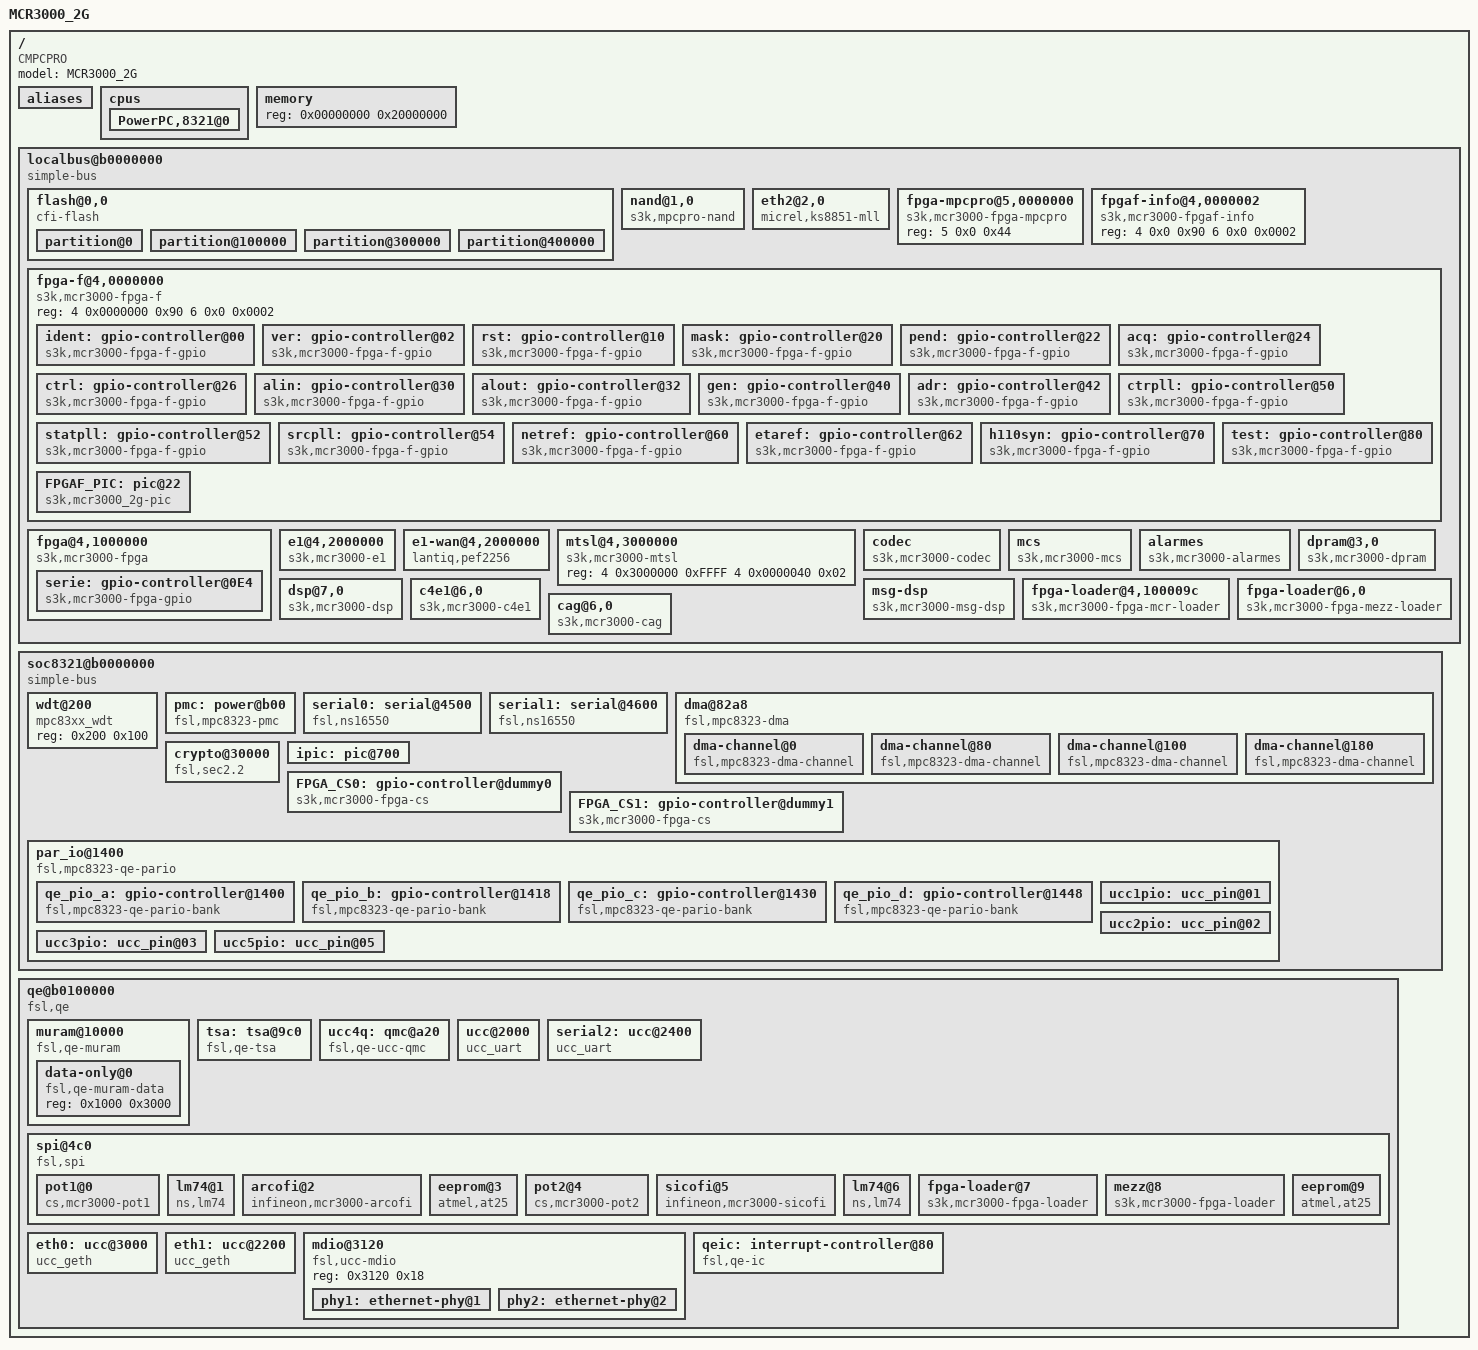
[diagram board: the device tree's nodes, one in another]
/*
 * MPC8321E Device Tree Source
 *
 * Copyright 2007 Freescale Semiconductor Inc.
 *
 * This program is free software; you can redistribute  it and/or modify it
 * under  the terms of  the GNU General  Public License as published by the
 * Free Software Foundation;  either version 2 of the  License, or (at your
 * option) any later version.
 */

/dts-v1/;

/ {
	model = "MCR3000_2G";
	compatible = "CMPCPRO", "MPC8321E", "MPC8323ERDB", "MPC832xRDB", "MPC83xxRDB", "fsl,base", "fsl,mpcpro";
	#address-cells = <1>;
	#size-cells = <1>;

	aliases {
		ethernet0 = &eth1;
		ethernet1 = &eth0;
		serial0 = &serial0;
		serial1 = &serial1;
		serial2 = &serial2;
	};

	cpus {
		#address-cells = <1>;
		#size-cells = <0>;

		PowerPC,8321@0 {
			device_type = "cpu";
			reg = <0x0>;
			d-cache-line-size = <0x20>;	// 32 bytes
			i-cache-line-size = <0x20>;	// 32 bytes
			d-cache-size = <16384>;	// L1, 16K
			i-cache-size = <16384>;	// L1, 16K
			timebase-frequency = <0>;
			bus-frequency = <0>;
			clock-frequency = <0>;
		};
	};

	memory {
		device_type = "memory";
		reg = <0x00000000 0x20000000>;
	};

	localbus@b0000000 {
		#address-cells = <2>;
		#size-cells = <1>;
		compatible = "simple-bus";
		ranges = <0 0x0 0x40000000 0x04000000	// Boot Flash
			  1 0x0 0xa0000000 0x00008000	// Nand Flash
			  2 0x0 0x92000000 0x00008000	// Eth Face avant
			  3 0x0 0x83400000 0x00010000	// DPRAM (DSP)
			  4 0x0 0x80000000 0x10000000	// Periphs
			  5 0x0 0x90000000 0x10000000	// FPGA-MPCPRO
			  6 0x0 0x81800000 0x00008000	// mezzanine
			  7 0x0 0x80800000 0x00008000>;	// DSP

//			  5 0x0 0x80000000 0x00800000>;	// FPGA-Firmware
//			  6 0x0 0x80800000 0x00800000	// DSP
//			  7 0x0 0x81000000 0x00800000	// FPGA-Radio
//			  8 0x0 0x81800000 0x00800000	// mezzanine
//			  9 0x0 0x82000000 0x00800000	// controleur E1
//			 10 0x0 0x83000000 0x00400000	// matrice
//			 11 0x0 0x83400000 0x00800000	// DPRAM (DSP)
//			 12 0x0 0x83c00000 0x00800000>;	// DPRAM (semaphores)
		reg = <0xb0000000 0x00000200>;
		bus-frequency = <0>;

		flash@0,0 {
			#address-cells = <1>;
			#size-cells = <1>;
			compatible = "cfi-flash";
			reg = <0x0 0x00000000 0x4000000>;
			bank-width = <2>;
			device-width = <2>;
			partition@0 {
				label = "boot";
				reg = <0x0 0x100000>;
			};
			partition@100000 {
				label = "other u-boot";
				reg = <0x100000 0x200000>;
			};
			partition@300000 {
				label = "dtb";
				reg = <0x300000 0x100000>;
			};
			partition@400000 {
				label = "kernel";
				reg = <0x400000 0x400000>;
			};
		};

		nand@1,0 {
			compatible = "s3k,mpcpro-nand";
			reg = <1 0x0 0x01>;
			#address-cells = <1>;
			#size-cells = <1>;
			gpios = <&qe_pio_c 24 1 	// RDY
				 0			// nCE, we use chip select
				 &qe_pio_c 26 1		// ALE
				 &qe_pio_c 25 1		// CLE
				 0>;			// nwp
			//partition@0 {
			//	label = "mpcpro-nand";
			//	reg = <0x0 0x4000>;
			//};
		};

		eth2@2,0 {
			compatible = "micrel,ks8851-mll";
			reg =  <2 0x00 0xff
				2 0x100 0xff>;
			interrupts = <21 0x8>;
			interrupt-parent = <&ipic>;
		};

		fpga-mpcpro@5,0000000 {
			#address-cells = <1>;
			#size-cells = <1>;
			compatible = "s3k,mcr3000-fpga-mpcpro";
			reg = <5 0x0 0x44>;
		};
		
		fpgaf-info@4,0000002 { // Driver KNL
			#address-cells = <1>;
			#size-cells = <1>;
			compatible = "s3k,mcr3000-fpgaf-info";
			reg = <4 0x0 0x90 6 0x0 0x0002>;	// Mappage registres FPGAF ; Ident carte Mezzanine
		};

		fpga-f@4,0000000 { // Driver LDB (deviendra peut etre obsolete)
			#address-cells = <1>;
			#size-cells = <1>;
			compatible = "s3k,mcr3000-fpga-f";
			reg = <4 0x0000000 0x90 6 0x0 0x0002>;
			ranges = <0 4 0x0000000 0x90>;
			ident: gpio-controller@00 {
				#gpio-cells = <2>;
				compatible = "s3k,mcr3000-fpga-f-gpio";
				reg = <0x00 2>;
				gpio-controller;
			};
			ver: gpio-controller@02 {
				#gpio-cells = <2>;
				compatible = "s3k,mcr3000-fpga-f-gpio";
				reg = <0x02 2>;
				gpio-controller;
			};
			rst: gpio-controller@10 {
				#gpio-cells = <2>;
				compatible = "s3k,mcr3000-fpga-f-gpio";
				reg = <0x10 2>;
				gpio-controller;
			};
			mask: gpio-controller@20 {
				#gpio-cells = <2>;
				compatible = "s3k,mcr3000-fpga-f-gpio";
				reg = <0x20 2>;
				gpio-controller;
			};
			pend: gpio-controller@22 {
				#gpio-cells = <2>;
				compatible = "s3k,mcr3000-fpga-f-gpio";
				reg = <0x22 2>;
				gpio-controller;
			};
			acq: gpio-controller@24 {
				#gpio-cells = <2>;
				compatible = "s3k,mcr3000-fpga-f-gpio";
				reg = <0x24 2>;
				gpio-controller;
			};
			ctrl: gpio-controller@26 {
				#gpio-cells = <2>;
				compatible = "s3k,mcr3000-fpga-f-gpio";
				reg = <0x26 2>;
				gpio-controller;
			};
			alin: gpio-controller@30 {
				#gpio-cells = <2>;
				compatible = "s3k,mcr3000-fpga-f-gpio";
				reg = <0x30 2>;
				interrupts = <255 255 255 255 255 255 255 255 8 9 10 11 12 13 14 15>;
				interrupt-parent = <&FPGAF_PIC>;
				gpio-controller;
			};
			alout: gpio-controller@32 {
				#gpio-cells = <2>;
				compatible = "s3k,mcr3000-fpga-f-gpio";
				reg = <0x32 2>;
				gpio-controller;
			};
			gen: gpio-controller@40 {
				#gpio-cells = <2>;
				compatible = "s3k,mcr3000-fpga-f-gpio";
				reg = <0x40 2>;
				gpio-controller;
			};
			adr: gpio-controller@42 {
				#gpio-cells = <2>;
				compatible = "s3k,mcr3000-fpga-f-gpio";
				reg = <0x42 2>;
				gpio-controller;
			};
			ctrpll: gpio-controller@50 {
				#gpio-cells = <2>;
				compatible = "s3k,mcr3000-fpga-f-gpio";
				reg = <0x50 2>;
				gpio-controller;
			};
			statpll: gpio-controller@52 {
				#gpio-cells = <2>;
				compatible = "s3k,mcr3000-fpga-f-gpio";
				reg = <0x52 2>;
				gpio-controller;
			};
			srcpll: gpio-controller@54 {
				#gpio-cells = <2>;
				compatible = "s3k,mcr3000-fpga-f-gpio";
				reg = <0x54 2>;
				gpio-controller;
			};
			netref: gpio-controller@60 {
				#gpio-cells = <2>;
				compatible = "s3k,mcr3000-fpga-f-gpio";
				reg = <0x60 2>;
				gpio-controller;
			};
			etaref: gpio-controller@62 {
				#gpio-cells = <2>;
				compatible = "s3k,mcr3000-fpga-f-gpio";
				reg = <0x62 2>;
				interrupts = <255 255 255 255 255 255 255 255 255 255 2 4 3 5 6 7>;
				interrupt-parent = <&FPGAF_PIC>;
				gpio-controller;
			};
			h110syn: gpio-controller@70 {
				#gpio-cells = <2>;
				compatible = "s3k,mcr3000-fpga-f-gpio";
				reg = <0x70 2>;
				gpio-controller;
			};
			test: gpio-controller@80 {
				#gpio-cells = <2>;
				compatible = "s3k,mcr3000-fpga-f-gpio";
				reg = <0x80 2>;
				gpio-controller;
			};
			FPGAF_PIC: pic@22 {
				interrupt-controller;
				#address-cells = <0>;
				#interrupt-cells = <1>;
				interrupts = <23 0>;
				interrupt-parent = <&ipic>;
				reg = <0x0 0x90>;	// Mappage registres FPGAF
				compatible = "s3k,mcr3000_2g-pic";
			};
		};
		
		fpga@4,1000000 {
			#address-cells = <1>;
			#size-cells = <1>;
			compatible = "s3k,mcr3000-fpga";
			reg = <4 0x1000000 0x0200 6 0x0 0x0002 4 0x60 0x02 4 0x10000E8 0x02>;
			/* registres FPGA - Registre ident MEZZ (1G) - Registre NetRef FPGAF - Registre BRG5 FPGA */
			ranges = <0 4 0x1000000 0x0200>;
			interrupts = <19 0>;
			interrupt-parent = <&ipic>;
			serie: gpio-controller@0E4 {
				#gpio-cells = <2>;
				compatible = "s3k,mcr3000-fpga-gpio";
				reg = <0x0E4 2>;
				gpio-controller;
			};
		};
		
		e1@4,2000000 {
			#address-cells = <1>;
			#size-cells = <1>;
			compatible = "s3k,mcr3000-e1";
			reg = <4 0x2000000 0xFF>;
			interrupts = <20 0>;
			interrupt-parent = <&ipic>;
		};

		e1-wan@4,2000000 {
			#address-cells = <1>;
			#size-cells = <1>;
			compatible = "lantiq,pef2256";
			reg = <4 0x2000000 0xFF>;
			data-rate = <2>;
			interrupts = <20 0>;
			interrupt-parent = <&ipic>;
		};
		
		mtsl@4,3000000 {
			#address-cells = <1>;
			#size-cells = <1>;
			compatible = "s3k,mcr3000-mtsl";
			reg = <4 0x3000000 0xFFFF 4 0x0000040 0x02>;
		};

		codec {
			compatible = "s3k,mcr3000-codec";
		};

		mcs {
			compatible = "s3k,mcr3000-mcs";
		};

		alarmes {
			compatible = "s3k,mcr3000-alarmes";
			gpios = <&alin 13 1 	// ACQ_ALRM
				&alout 15 1	// ALRM_MAJ
				&alout 14 1>;	// ALRM_MIN
		};
		
		dpram@3,0 {
			#address-cells = <1>;
			#size-cells = <1>;
			compatible = "s3k,mcr3000-dpram";
			reg = <3 0x0 0x10000>;
			interrupts = <18 0>;
			interrupt-parent = <&ipic>;
		};

		dsp@7,0 {
			#address-cells = <1>;
			#size-cells = <1>;
			compatible = "s3k,mcr3000-dsp";
			reg = <7 0x0 0x0008 5 0x100 0x02>;
			interrupts = <0 1>;
			interrupt-parent = <&FPGAF_PIC>;
		};

		msg-dsp {
			#address-cells = <1>;
			#size-cells = <1>;
			compatible = "s3k,mcr3000-msg-dsp";
			reg = <3 0x0 0x300>;
			interrupts = <0 1>;
			interrupt-parent = <&FPGAF_PIC>;
		};
		
		fpga-loader@4,100009c {
			#address-cells = <1>;
			#size-cells = <1>;
			compatible = "s3k,mcr3000-fpga-mcr-loader";
			reg = <4 0x100009c 2 4 0 0 4 0x10000e2 2>;	/* Version FPGA ; NULL ; RSERIE */
			gpios = <&FPGA_CS0 1 1		/* INIT FPGA */
				 &qe_pio_a 11 1		/* DONE FPGA */
				 &rst 13 1 >;		/* RST FPGA */
		};
		
		c4e1@6,0 {
			#address-cells = <1>;
			#size-cells = <1>;
			compatible = "s3k,mcr3000-c4e1";
			reg = <6 0x0 0x600>;
			interrupts = <22 0>;
			interrupt-parent = <&ipic>;
		};

		fpga-loader@6,0 {
			#address-cells = <1>;
			#size-cells = <1>;
			compatible = "s3k,mcr3000-fpga-mezz-loader";
			reg = <6 0x500 2>; 		/* Version FPGA Mezz */
			gpios = <&FPGA_CS1 1 1		/* INIT Mezz */
				&qe_pio_b 11 1		/* DONE Mezz */
				&rst 9 1 >;		/* RST Mezz */
		};

		cag@6,0 {
			#address-cells = <1>;
			#size-cells = <1>;
			compatible = "s3k,mcr3000-cag";
			reg = <6 0x0 0x0020>;
			interrupts = <22 0>;
			interrupt-parent = <&ipic>;
		};
	};

	soc8321@b0000000 {
		#address-cells = <1>;
		#size-cells = <1>;
		device_type = "soc";
		compatible = "simple-bus";
		ranges = <0x0 0xb0000000 0x00100000>;
		reg = <0xb0000000 0x00000200>;
		bus-frequency = <0>;
		
		wdt@200 {
			device_type = "watchdog";
			compatible = "mpc83xx_wdt";
			reg = <0x200 0x100>;
		};

		pmc: power@b00 {
			compatible = "fsl,mpc8323-pmc", "fsl,mpc8349-pmc";
			reg = <0xb00 0x100 0xa00 0x100>;
			interrupts = <80 0x8>;
			interrupt-parent = <&ipic>;
		};

		serial0: serial@4500 {
			cell-index = <0>;
			device_type = "serial";
			compatible = "fsl,ns16550", "ns16550";
			reg = <0x4500 0x100>;
			clock-frequency = <0>;
			interrupts = <9 0x8>;
			interrupt-parent = <&ipic>;
		};

		serial1: serial@4600 {
			cell-index = <1>;
			device_type = "serial";
			compatible = "fsl,ns16550", "ns16550";
			reg = <0x4600 0x100>;
			clock-frequency = <0>;
			interrupts = <10 0x8>;
			interrupt-parent = <&ipic>;
		};

		dma@82a8 {
			#address-cells = <1>;
			#size-cells = <1>;
			compatible = "fsl,mpc8323-dma", "fsl,elo-dma";
			reg = <0x82a8 4>;
			ranges = <0 0x8100 0x1a8>;
			interrupt-parent = <&ipic>;
			interrupts = <71 8>;
			cell-index = <0>;
			dma-channel@0 {
				compatible = "fsl,mpc8323-dma-channel", "fsl,elo-dma-channel";
				reg = <0 0x80>;
				cell-index = <0>;
				interrupt-parent = <&ipic>;
				interrupts = <71 8>;
			};
			dma-channel@80 {
				compatible = "fsl,mpc8323-dma-channel", "fsl,elo-dma-channel";
				reg = <0x80 0x80>;
				cell-index = <1>;
				interrupt-parent = <&ipic>;
				interrupts = <71 8>;
			};
			dma-channel@100 {
				compatible = "fsl,mpc8323-dma-channel", "fsl,elo-dma-channel";
				reg = <0x100 0x80>;
				cell-index = <2>;
				interrupt-parent = <&ipic>;
				interrupts = <71 8>;
			};
			dma-channel@180 {
				compatible = "fsl,mpc8323-dma-channel", "fsl,elo-dma-channel";
				reg = <0x180 0x28>;
				cell-index = <3>;
				interrupt-parent = <&ipic>;
				interrupts = <71 8>;
			};
		};

		crypto@30000 {
			compatible = "fsl,sec2.2", "fsl,sec2.1", "fsl,sec2.0";
			reg = <0x30000 0x10000>;
			interrupts = <11 0x8>;
			interrupt-parent = <&ipic>;
			fsl,num-channels = <1>;
			fsl,channel-fifo-len = <24>;
			fsl,exec-units-mask = <0x4c>;
			fsl,descriptor-types-mask = <0x0122003f>;
			sleep = <&pmc 0x03000000>;
		};

		ipic:pic@700 {
			interrupt-controller;
			#address-cells = <0>;
			#interrupt-cells = <2>;
			reg = <0x700 0x100>;
			device_type = "ipic";
		};

		FPGA_CS0: gpio-controller@dummy0 {	//FPGA Radio
			#gpio-cells = <2>;
			compatible = "s3k,mcr3000-fpga-cs";
			gpio-controller;
			reg = <0x0 0x1>;	// necessaire mais non utilise
			gpios = <&qe_pio_c 21 1		//PROG
				 &qe_pio_b 23 1>; 	//INIT
		};
		FPGA_CS1: gpio-controller@dummy1 {	//FPGA Mezz
			#gpio-cells = <2>;
			compatible = "s3k,mcr3000-fpga-cs";
			gpio-controller;
			reg = <0x1 0x1>; /* necessaire mais non utilise */
			gpios = <&qe_pio_b 29 1		//PROG
				 &qe_pio_b 15 1>; 	//INIT
		};


		par_io@1400 {
			#address-cells = <1>;
			#size-cells = <1>;
			reg = <0x1400 0x100>;
			ranges = < 0 0 0xb0001400 0x18
				   1 0 0xb0001418 0x18
				   2 0 0xb0001430 0x18
				   3 0 0xb0001448 0x18>;
			compatible = "fsl,mpc8323-qe-pario";
			device_type = "par_io";
			num-ports = <7>;

			qe_pio_a: gpio-controller@1400 {
				#gpio-cells = <2>;
				compatible = "fsl,mpc8323-qe-pario-bank";
				reg = <0x1400 0x18>;
				gpio-controller;
			};

			qe_pio_b: gpio-controller@1418 {
				#gpio-cells = <2>;
				compatible = "fsl,mpc8323-qe-pario-bank";
				reg = <0x1418 0x18>;
				gpio-controller;
			};

			qe_pio_c: gpio-controller@1430 {
				#gpio-cells = <2>;
				compatible = "fsl,mpc8323-qe-pario-bank";
				reg = <0x1430 0x18>;
				gpio-controller;
			};

			qe_pio_d: gpio-controller@1448 {
				#gpio-cells = <2>;
				compatible = "fsl,mpc8323-qe-pario-bank";
				reg = <0x1448 0x18>;
				gpio-controller;
			};

			ucc1pio:ucc_pin@01 {
				pio-map = <
				/*
				 *    		      open       has
				 *   port  pin  dir  drain  sel  irq
				 */
					0    0    1      0    1    0  /* SER1_TxD0 */
					0    4    2      0    1    0  /* SER1_RXD0 */
					0    8    0      0    1    0  /* CD */
					0   12    0      0    0    0  /* SER1_RTS */
					0   10    1      0    0    0  /* SER1_CTS */
				>;
			};
			ucc2pio:ucc_pin@02 {
				pio-map = <
			/* port  pin  dir  open_drain  assignment  has_irq */
				3  4  3  0  2  0 	/* MDIO */
				3  5  1  0  2  0 	/* MDC */

				0 18  1  0  1  0	/* R1_TXD0 */
				0 19  1  0  1  0	/* R1_TXD1 */
				0 22  2  0  1  0	/* R1_RXD0 */
				0 23  2  0  1  0	/* R1_RXD1 */
				0 30  1  0  1  0	/* R1_TXEN */
				0 28  2  0  1  0	/* R1_CRS_DV */
				0 26  2  0  1  0	/* R1_RXER */
				3 10  2  0  3  0>;	/* R1_REF_CLK */
			};
			ucc3pio:ucc_pin@03 {
				pio-map = <
			/* port  pin  dir  open_drain  assignment  has_irq */
				1  0  1  0  1  0	/* R2_TXD0 */
				1  1  1  0  1  0	/* R2_TXD1 */
				1  4  2  0  1  0	/* R2_RXD0 */
				1  5  2  0  1  0	/* R2_RXD1 */
				1 12  1  0  1  0	/* R2_TXEN */
				1 10  2  0  1  0	/* R2_CRS_DV */
				1  8  2  0  1  0	/* R2_RXER */
				1 14  2  0  1  0>;	/* R2_REF_CLK */
			};
			ucc5pio:ucc_pin@05 {
				pio-map = <
				/*
				 *    		      open       has
				 *   port  pin  dir  drain  sel  irq
				 */
					2    0    1      0    2    0  /* TxD5 */
					2    8    2      0    2    0  /* RxD5 */
					2   24    0      0    2    0  /* CD */

					2   29    0      0    2    1  /* CTS5 */
					2   31    1      0    0    0  /* RTS5 */
				>;
			};
		};
	};

	qe@b0100000 {
		#address-cells = <1>;
		#size-cells = <1>;
		device_type = "qe";
		compatible = "fsl,qe";
		ranges = <0x0 0xb0100000 0x00100000>;
		reg = <0xb0100000 0x480>;
		brg-frequency = <0>;
		bus-frequency = <198000000>;
		fsl,qe-num-riscs = <1>;
		fsl,qe-num-snums = <28>;

		muram@10000 {
 			#address-cells = <1>;
 			#size-cells = <1>;
			compatible = "fsl,qe-muram", "fsl,cpm-muram";
			ranges = <0x0 0x00010000 0x00004000>;

			/* conserver les 4 premiers Kbytes pour QMC */
			data-only@0 {
				compatible = "fsl,qe-muram-data",
					     "fsl,cpm-muram-data";
				reg = <0x1000 0x3000>;
			};
		};

		tsa: tsa@9c0 {
			compatible = "fsl,qe-tsa";
			reg = <0x9c0 0x1>;	/* necessaire mais non utilise */
			/* parametres possible : none, UCC4 */
			ucc_qmc_mcr = "UCC4";
			/* parametre enregistrement : TS sup 0 a 16 */
			ts_enreg = <16>;
		};

		ucc4q: qmc@a20 {
			device_type = "qmc";
			compatible = "fsl,qe-ucc-qmc";
			cell-index = <4>;	/* The UCC number, 1-7*/
			reg = <0x3200 0x200 0x10000 0x1000>;
			interrupts = <35>;
			interrupt-parent = <&qeic>;
			clock-name = "clk1";
		};

		ucc@2000 {
			device_type = "serial";
			compatible = "ucc_uart";
			cell-index = <1>;	/* The UCC number, 1-7*/
			port-number = <1>;	/* Which ttyQEx device */
			soft-uart;		/* We need Soft-UART */
			reg = <0x2000 0x200>;
			interrupts = <32>;	/* From Table 18-12 */
			interrupt-parent = < &qeic >;
			/*
			 * For Soft-UART, we need to set TX to 1X, which
			 * means specifying separate clock sources.
			 */
			rx-clock-name = "brg7";
			tx-clock-name = "brg1";
			pio-handle = < &ucc1pio >;
		};

		serial2: ucc@2400 {
			device_type = "serial";
			compatible = "ucc_uart";
			cell-index = <5>;	/* The UCC number, 1-7*/
			port-number = <0>;	/* Which ttyQEx device */
			soft-uart;		/* We need Soft-UART */
			reg = <0x2400 0x200>;
			interrupts = <40>;	/* From Table 18-12 */
			interrupt-parent = < &qeic >;
			/*
			 * For Soft-UART, we need to set TX to 1X, which
			 * means specifying separate clock sources.
			 */
			rx-clock-name = "brg6";
			tx-clock-name = "brg5";
//			pio-handle = < &ucc5pio >;
		};

		spi@4c0 {
			#address-cells = <1>;
			#size-cells = <0>;
			cell-index = <0>;
			compatible = "fsl,spi";
			reg = <0x4c0 0x40>;
			interrupts = <2>;
			interrupt-parent = <&qeic>;
			mode = "qe";
			gpios = <&qe_pio_c  27  1		/* POT1 */
				 &qe_pio_c   5  1		/* TEMP carte base */
				 &qe_pio_c  28  1		/* CS_CODEC_F/ARCOFI */
				 &qe_pio_c   2  1		/* EEPROM carte base */

				 &qe_pio_a  29  1		/* POT2 */
				 &qe_pio_b  16  1		/* CS_CODEC_R/SICOFI */
				 &qe_pio_c   3  1		/* TEMP MPCPRO */
				 &FPGA_CS0   0  1		/* FPGA Radio */
				 &FPGA_CS1   0  1		/* FPGA Mezz */
				 &qe_pio_d   3  1>;		/* EEPROM MPCPRO */
				

			pot1@0 {
				compatible = "cs,mcr3000-pot1";
				spi-max-frequency = <1000000>;
				reg = <0>;
				spi-cs-high;
			};
			lm74@1 {
				compatible = "ns,lm74";
				spi-max-frequency = <1000000>;
				reg = <1>;
				spi-cs-high;
			};
			arcofi@2 {
				compatible = "infineon,mcr3000-arcofi";
				spi-max-frequency = <1000000>;
				reg = <2>;
				spi-cs-high;
				spi-cpha;
				spi-troll;
			};
			eeprom@3 {
				compatible = "atmel,at25", "cs,eeprom";
				spi-max-frequency = <1000000>;
				reg = <3>;
				spi-cs-high;
				at25,byte-len = <1024>;
				at25,addr-mode = <2>;
				at25,page-size = <32>;
			};
			pot2@4 {
				compatible = "cs,mcr3000-pot2";
				spi-max-frequency = <1000000>;
				reg = <4>;
				spi-cs-high;
			};
			sicofi@5 {
				compatible = "infineon,mcr3000-sicofi";
				spi-max-frequency = <1000000>;
				reg = <5>;
				spi-cs-high;
				spi-cpha;
				spi-troll;
			};
			lm74@6 {
				compatible = "ns,lm74";
				spi-max-frequency = <1000000>;
				reg = <6>;
				spi-cs-high;
			};
			fpga-loader@7 {
				compatible = "s3k,mcr3000-fpga-loader";
				spi-max-frequency = <10000000>;
				reg = <7>;
				spi-cs-high;
				loader = "mcr";
				spi-bits = <16>;
			};
			mezz@8 {
				compatible = "s3k,mcr3000-fpga-loader";
				spi-max-frequency = <10000000>;
				reg = <8>;
				spi-cs-high;
				loader = "mezz";
				spi-bits = <16>;
			};
			eeprom@9 {
				compatible = "atmel,at25", "cs,eeprom";
				spi-max-frequency = <1000000>;
				reg = <9>;
				spi-cs-high;
				at25,byte-len = <1024>;
				at25,addr-mode = <2>;
				at25,page-size = <32>;
			};
		};

		eth0: ucc@3000 {
			device_type = "network";
			compatible = "ucc_geth";
			cell-index = <2>;
			reg = <0x3000 0x200>;
			interrupts = <33>;
			interrupt-parent = <&qeic>;
			local-mac-address = [ 00 00 00 00 00 00 ];
			rx-clock-name = "clk17";
			tx-clock-name = "clk17";
			phy-handle = <&phy1>;
			pio-handle = <&ucc2pio>;
			phy-connection-type = "rmii";
		};

		eth1: ucc@2200 {
			device_type = "network";
			compatible = "ucc_geth";
			cell-index = <3>;
			reg = <0x2200 0x200>;
			interrupts = <34>;
			interrupt-parent = <&qeic>;
			local-mac-address = [ 00 00 00 00 00 00 ];
			rx-clock-name = "clk12";
			tx-clock-name = "clk12";
			phy-handle = <&phy2>;
			pio-handle = <&ucc3pio>;
			phy-connection-type = "rmii";
		};

		mdio@3120 {
			#address-cells = <1>;
			#size-cells = <0>;
			reg = <0x3120 0x18>;
			compatible = "fsl,ucc-mdio";

			phy1:ethernet-phy@1 {
				interrupt-parent = <&ipic>;
				reg = <0x1>;
				interrupts = <17 8>;
				device_type = "ethernet-phy";
			};
			phy2:ethernet-phy@2 {
				interrupt-parent = <&ipic>;
				reg = <0x2>;	
				interrupts = <17 8>;
				device_type = "ethernet-phy";
			};
		};

		qeic:interrupt-controller@80 {
			interrupt-controller;
			compatible = "fsl,qe-ic";
			#address-cells = <0>;
			#interrupt-cells = <1>;
			reg = <0x80 0x80>;
			big-endian;
			interrupts = <32 0x8 33 0x8>; //high:32 low:33
			interrupt-parent = <&ipic>;
		};
	};
};
